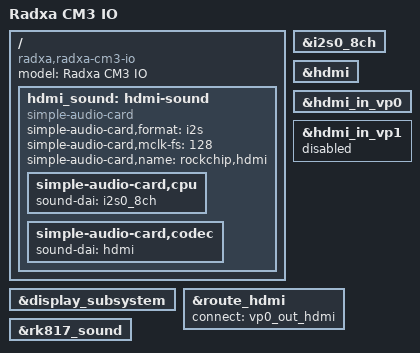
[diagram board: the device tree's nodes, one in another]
// SPDX-License-Identifier: (GPL-2.0+ OR MIT)
/*
 * Copyright (c) 2020 Rockchip Electronics Co., Ltd.
 * Copyright (c) 2021 Radxa Limited.
 *
 */

/dts-v1/;

#include "rk3566-radxa-rock-3-compute-module.dtsi"

/ {
	model = "Radxa CM3 IO";
	compatible = "radxa,radxa-cm3-io", "rockchip,rk3566";

	hdmi_sound: hdmi-sound {
		compatible = "simple-audio-card";
		simple-audio-card,format = "i2s";
		simple-audio-card,mclk-fs = <128>;
		simple-audio-card,name = "rockchip,hdmi";

		simple-audio-card,cpu {
				sound-dai = <&i2s0_8ch>;
		};
		simple-audio-card,codec {
				sound-dai = <&hdmi>;
		};
	};

};

&i2s0_8ch {
	status = "okay";
};

&display_subsystem {
    status = "okay";
};

&hdmi {
	status = "okay";
};

&hdmi_in_vp0 {
	status = "okay";
};

&hdmi_in_vp1 {
	status = "disabled";
};

&hdmi_sound {
	status = "okay";
};

&route_hdmi {
	status = "okay";
	connect = <&vp0_out_hdmi>;
};

&rk817_sound {
	status = "okay";
};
